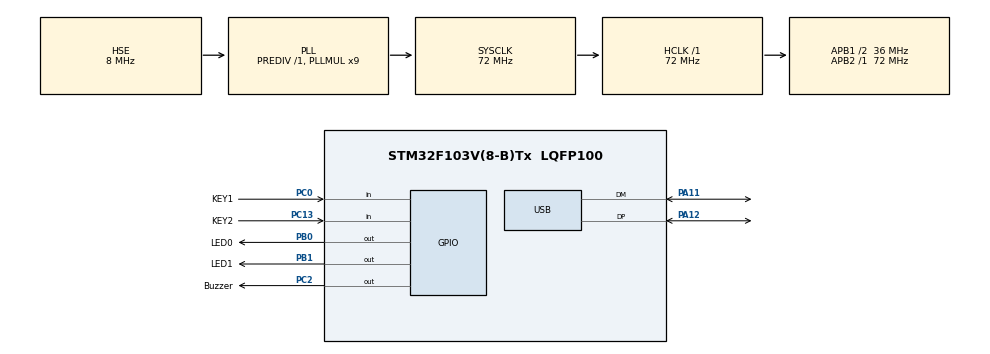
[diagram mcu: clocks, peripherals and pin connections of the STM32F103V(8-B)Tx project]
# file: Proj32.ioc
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Mcu.Family=STM32F1
Mcu.Name=STM32F103V(8-B)Tx
Mcu.Package=LQFP100
NVIC.PriorityGroup=NVIC_PRIORITYGROUP_4
NVIC.USB_LP_CAN1_RX0_IRQn=true\:0\:0\:false\:false\:true\:false\:true
OSC_IN.Mode=HSE-External-Oscillator
OSC_IN.Signal=RCC_OSC_IN
OSC_OUT.Mode=HSE-External-Oscillator
OSC_OUT.Signal=RCC_OSC_OUT
PA11.Mode=Device
PA11.Signal=USB_DM
PA12.Mode=Device
PA12.Signal=USB_DP
PA13.Mode=Serial_Wire
PA13.Signal=SYS_JTMS-SWDIO
PA14.Mode=Serial_Wire
PA14.Signal=SYS_JTCK-SWCLK
PB0.GPIO_Label=LED0
PB0.GPIO_ModeDefaultOutputPP=GPIO_MODE_OUTPUT_PP
PB0.GPIO_PuPd=GPIO_PULLUP
PB0.GPIO_Speed=GPIO_SPEED_FREQ_HIGH
PB0.PinState=GPIO_PIN_SET
PB0.Signal=GPIO_Output
PB1.GPIO_Label=LED1
PB1.GPIO_PuPd=GPIO_PULLDOWN
PB1.GPIO_Speed=GPIO_SPEED_FREQ_HIGH
PB1.PinState=GPIO_PIN_SET
PB1.Signal=GPIO_Output
PC0.GPIO_Label=KEY1
PC0.GPIO_PuPd=GPIO_PULLDOWN
PC0.Signal=GPIO_Input
PC13-TAMPER-RTC.GPIO_Label=KEY2
PC13-TAMPER-RTC.GPIO_PuPd=GPIO_PULLDOWN
PC13-TAMPER-RTC.Signal=GPIO_Input
PC2.GPIO_Label=Buzzer
PC2.GPIO_PuPd=GPIO_PULLDOWN
PC2.GPIO_Speed=GPIO_SPEED_FREQ_HIGH
PC2.PinState=GPIO_PIN_SET
PC2.Signal=GPIO_Output
ProjectManager.HeapSize=0x1000
ProjectManager.StackSize=0x1000
ProjectManager.TargetToolchain=STM32CubeIDE
RCC.AHBFreq_Value=72000000
RCC.APB1CLKDivider=RCC_HCLK_DIV2
RCC.APB1Freq_Value=36000000
RCC.APB1TimFreq_Value=72000000
RCC.APB2Freq_Value=72000000
RCC.APB2TimFreq_Value=72000000
RCC.HCLKFreq_Value=72000000
RCC.PLLMUL=RCC_PLL_MUL9
RCC.SYSCLKFreq_VALUE=72000000
RCC.SYSCLKSource=RCC_SYSCLKSOURCE_PLLCLK
RCC.USBFreq_Value=48000000
RCC.USBPrescaler=RCC_USBCLKSOURCE_PLL_DIV1_5
USB_DEVICE.CLASS_NAME_FS=CDC
USB_DEVICE.VirtualMode=Cdc
USB_DEVICE.VirtualModeFS=Cdc_FS
VP_USB_DEVICE_VS_USB_DEVICE_CDC_FS.Mode=CDC_FS
board=custom

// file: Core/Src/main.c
/* USER CODE BEGIN Header */
/**
  ******************************************************************************
  * @file           : main.c
  * @brief          : Main program body
  ******************************************************************************
  * @attention
  *
  * Copyright (c) 2021 STMicroelectronics.
  * All rights reserved.
  *
  * This software is licensed under terms that can be found in the LICENSE file
  * in the root directory of this software component.
  * If no LICENSE file comes with this software, it is provided AS-IS.
  *
  ******************************************************************************
  */
/* USER CODE END Header */
#include "main.h"
#include "usb_device.h"

void SystemClock_Config(void);
static void MX_GPIO_Init(void);

int main(void)
{

  /* MCU Configuration--------------------------------------------------------*/

  /* Reset of all peripherals, Initializes the Flash interface and the Systick. */
  HAL_Init();

  /* Configure the system clock */
  SystemClock_Config();

  /* Initialize all configured peripherals */
  MX_GPIO_Init();
  MX_USB_DEVICE_Init();

  /* Infinite loop */
  /* USER CODE BEGIN WHILE */
  while (1)
  {
      char temp;
      //获取KEY的状态，按下为1，弹起为0
      temp = HAL_GPIO_ReadPin(KEY1_GPIO_Port,KEY1_Pin);//获取按键KEY1状态
      if(temp == 1)
      {   //按下时，点亮LED0
          HAL_GPIO_WritePin(LED0_GPIO_Port,LED0_Pin,GPIO_PIN_RESET);
      }
      else
      {   //弹起时，关闭LED0
          HAL_GPIO_WritePin(LED0_GPIO_Port,LED0_Pin,GPIO_PIN_SET);
      }
    /* USER CODE END WHILE */

  }
}

void SystemClock_Config(void)
{
  RCC_OscInitTypeDef RCC_OscInitStruct = {0};
  RCC_ClkInitTypeDef RCC_ClkInitStruct = {0};
  RCC_PeriphCLKInitTypeDef PeriphClkInit = {0};

  /** Initializes the RCC Oscillators according to the specified parameters
  * in the RCC_OscInitTypeDef structure.
  */
  RCC_OscInitStruct.OscillatorType = RCC_OSCILLATORTYPE_HSE;
  RCC_OscInitStruct.HSEState = RCC_HSE_ON;
  RCC_OscInitStruct.HSEPredivValue = RCC_HSE_PREDIV_DIV1;
  RCC_OscInitStruct.HSIState = RCC_HSI_ON;
  RCC_OscInitStruct.PLL.PLLState = RCC_PLL_ON;
  RCC_OscInitStruct.PLL.PLLSource = RCC_PLLSOURCE_HSE;
  RCC_OscInitStruct.PLL.PLLMUL = RCC_PLL_MUL9;
  if (HAL_RCC_OscConfig(&RCC_OscInitStruct) != HAL_OK)
  {
    Error_Handler();
  }
  /** Initializes the CPU, AHB and APB buses clocks
  */
  RCC_ClkInitStruct.ClockType = RCC_CLOCKTYPE_HCLK|RCC_CLOCKTYPE_SYSCLK
                              |RCC_CLOCKTYPE_PCLK1|RCC_CLOCKTYPE_PCLK2;
  RCC_ClkInitStruct.SYSCLKSource = RCC_SYSCLKSOURCE_PLLCLK;
  RCC_ClkInitStruct.AHBCLKDivider = RCC_SYSCLK_DIV1;
  RCC_ClkInitStruct.APB1CLKDivider = RCC_HCLK_DIV2;
  RCC_ClkInitStruct.APB2CLKDivider = RCC_HCLK_DIV1;

  if (HAL_RCC_ClockConfig(&RCC_ClkInitStruct, FLASH_LATENCY_2) != HAL_OK)
  {
    Error_Handler();
  }
  PeriphClkInit.PeriphClockSelection = RCC_PERIPHCLK_USB;
  PeriphClkInit.UsbClockSelection = RCC_USBCLKSOURCE_PLL_DIV1_5;
  if (HAL_RCCEx_PeriphCLKConfig(&PeriphClkInit) != HAL_OK)
  {
    Error_Handler();
  }
}

static void MX_GPIO_Init(void)
{
  GPIO_InitTypeDef GPIO_InitStruct = {0};

  /* GPIO Ports Clock Enable */
  __HAL_RCC_GPIOC_CLK_ENABLE();
  __HAL_RCC_GPIOB_CLK_ENABLE();
  __HAL_RCC_GPIOA_CLK_ENABLE();

  /*Configure GPIO pin Output Level */
  HAL_GPIO_WritePin(Buzzer_GPIO_Port, Buzzer_Pin, GPIO_PIN_SET);

  /*Configure GPIO pin Output Level */
  HAL_GPIO_WritePin(GPIOB, LED0_Pin|LED1_Pin, GPIO_PIN_SET);

  /*Configure GPIO pins : KEY2_Pin KEY1_Pin */
  GPIO_InitStruct.Pin = KEY2_Pin|KEY1_Pin;
  GPIO_InitStruct.Mode = GPIO_MODE_INPUT;
  GPIO_InitStruct.Pull = GPIO_PULLDOWN;
  HAL_GPIO_Init(GPIOC, &GPIO_InitStruct);

  /*Configure GPIO pin : Buzzer_Pin */
  GPIO_InitStruct.Pin = Buzzer_Pin;
  GPIO_InitStruct.Mode = GPIO_MODE_OUTPUT_PP;
  GPIO_InitStruct.Pull = GPIO_PULLDOWN;
  GPIO_InitStruct.Speed = GPIO_SPEED_FREQ_HIGH;
  HAL_GPIO_Init(Buzzer_GPIO_Port, &GPIO_InitStruct);

  /*Configure GPIO pin : LED0_Pin */
  GPIO_InitStruct.Pin = LED0_Pin;
  GPIO_InitStruct.Mode = GPIO_MODE_OUTPUT_PP;
  GPIO_InitStruct.Pull = GPIO_PULLUP;
  GPIO_InitStruct.Speed = GPIO_SPEED_FREQ_HIGH;
  HAL_GPIO_Init(LED0_GPIO_Port, &GPIO_InitStruct);

  /*Configure GPIO pin : LED1_Pin */
  GPIO_InitStruct.Pin = LED1_Pin;
  GPIO_InitStruct.Mode = GPIO_MODE_OUTPUT_PP;
  GPIO_InitStruct.Pull = GPIO_PULLDOWN;
  GPIO_InitStruct.Speed = GPIO_SPEED_FREQ_HIGH;
  HAL_GPIO_Init(LED1_GPIO_Port, &GPIO_InitStruct);

}

void Error_Handler(void)
{
  __disable_irq();
  while (1)
  {
  }
}
